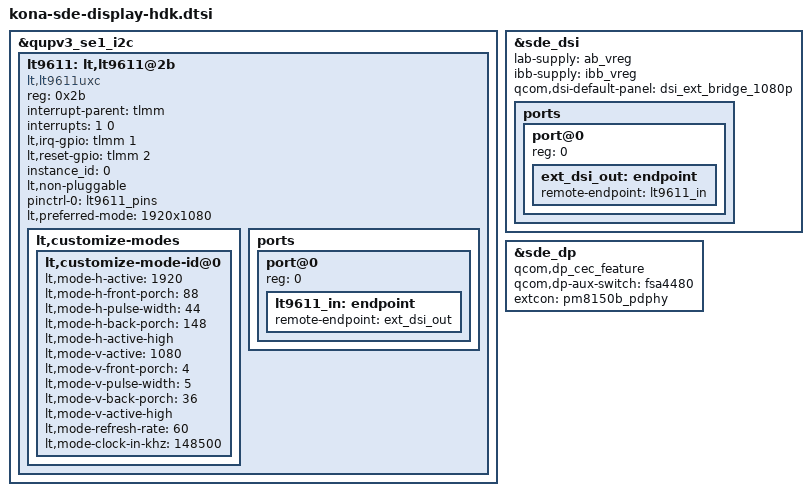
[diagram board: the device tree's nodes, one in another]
#include "kona-sde-display.dtsi"

&qupv3_se1_i2c {
	status = "ok";
	lt9611: lt,lt9611@2b {
		compatible = "lt,lt9611uxc";
		reg = <0x2b>;
		interrupt-parent = <&tlmm>;
		interrupts = <1 0>;
		interrupt-names = "lt_irq";
		lt,irq-gpio = <&tlmm 1 0x0>;
		lt,reset-gpio = <&tlmm 2 0x0>;
		instance_id = <0>;
		lt,non-pluggable;

		pinctrl-names = "default";
		pinctrl-0 = <&lt9611_pins>;

		lt,preferred-mode = "1920x1080";

		lt,customize-modes {
			lt,customize-mode-id@0 {
				lt,mode-h-active = <1920>;
				lt,mode-h-front-porch = <88>;
				lt,mode-h-pulse-width = <44>;
				lt,mode-h-back-porch = <148>;
				lt,mode-h-active-high;
				lt,mode-v-active = <1080>;
				lt,mode-v-front-porch = <4>;
				lt,mode-v-pulse-width = <5>;
				lt,mode-v-back-porch = <36>;
				lt,mode-v-active-high;
				lt,mode-refresh-rate = <60>;
				lt,mode-clock-in-khz = <148500>;
			};
		};

		ports {
			#address-cells = <1>;
			#size-cells = <0>;

			port@0 {
				reg = <0>;
				lt9611_in: endpoint {
					remote-endpoint = <&ext_dsi_out>;
				};
			};
		};
	};
};

&sde_dsi {
	lab-supply = <&ab_vreg>;
	ibb-supply = <&ibb_vreg>;
	qcom,dsi-default-panel = <&dsi_ext_bridge_1080p>;

	ports {
		#address-cells = <1>;
		#size-cells = <0>;

		port@0 {
			reg = <0>;
			ext_dsi_out: endpoint {
				remote-endpoint = <&lt9611_in>;
			};
		};
	};
};

&sde_dp {
	qcom,dp_cec_feature;
	qcom,dp-aux-switch = <&fsa4480>;
	extcon = <&pm8150b_pdphy>;
};

